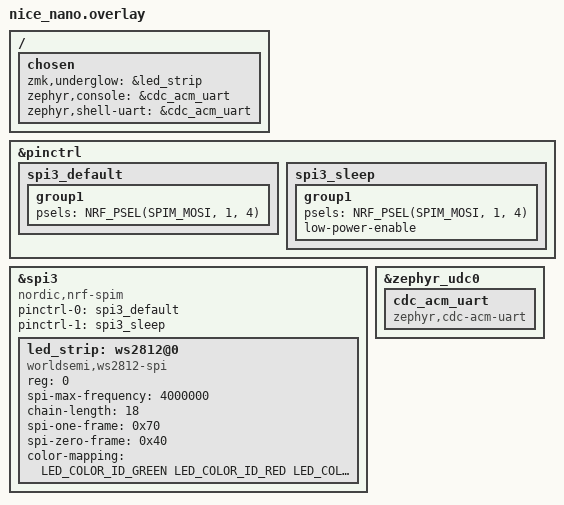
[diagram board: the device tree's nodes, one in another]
#include <dt-bindings/led/led.h>

&pinctrl {
    spi3_default: spi3_default {
        group1 {
            psels = <NRF_PSEL(SPIM_MOSI, 1, 4)>;
        };
    };

    spi3_sleep: spi3_sleep {
        group1 {
            psels = <NRF_PSEL(SPIM_MOSI, 1, 4)>;
            low-power-enable;
        };
    };
};

&spi3 {
    compatible = "nordic,nrf-spim";
    status = "okay";

    pinctrl-0 = <&spi3_default>;
    pinctrl-1 = <&spi3_sleep>;
    pinctrl-names = "default", "sleep";

    led_strip: ws2812@0 {
        compatible = "worldsemi,ws2812-spi";

        /* SPI */
        reg = <0>; /* ignored, but necessary for SPI bindings */
        spi-max-frequency = <4000000>;

        /* WS2812 */
        chain-length = <18>; /* arbitrary; change at will */
        spi-one-frame = <0x70>;
        spi-zero-frame = <0x40>;

        color-mapping = <LED_COLOR_ID_GREEN LED_COLOR_ID_RED LED_COLOR_ID_BLUE>;
    };
};

/ {
    chosen {
        zmk,underglow = &led_strip;
    };
};

/*
 * Console / logging transport
 *
 * This shield hands `uart0` to the PS/2 trackpoint driver (see
 * config/include/mouse_tp.dtsi), so the board has no serial port left to serve
 * as `zephyr,console`. ZMK's `CONFIG_ZMK_USB_LOGGING` selects `USB_UART_CONSOLE`
 * and therefore *requires* a console node; upstream ZMK normally supplies it
 * via the `zmk-usb-logging` snippet, but ZMK's build action only accepts one
 * `snippet:` per build entry and that slot holds `studio-rpc-usb-uart`.
 *
 * Declaring the CDC-ACM console inline, mirroring the upstream
 * `zmk-usb-logging` snippet and the original zmk-ps2 fork's board dtsi.
 */
/ {
    chosen {
        zephyr,console = &cdc_acm_uart;
        zephyr,shell-uart = &cdc_acm_uart;
    };
};

&zephyr_udc0 {
    cdc_acm_uart: cdc_acm_uart {
        compatible = "zephyr,cdc-acm-uart";
    };
};
